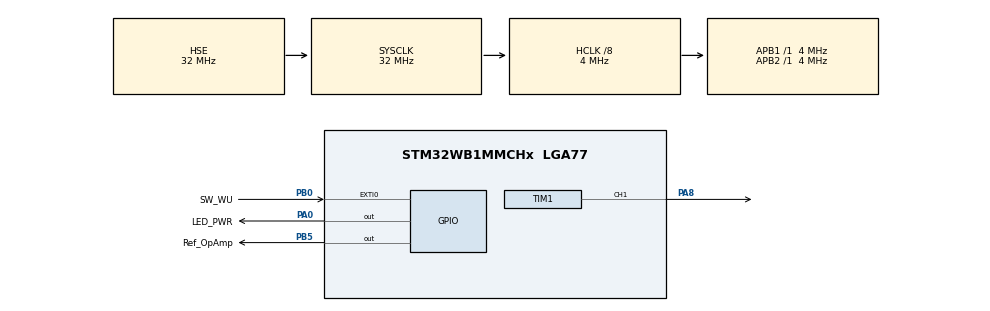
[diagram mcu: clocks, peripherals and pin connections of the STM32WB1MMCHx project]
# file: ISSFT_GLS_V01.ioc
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Mcu.Family=STM32WB
Mcu.Name=STM32WB1MMCHx
Mcu.Package=LGA77
NVIC.EXTI0_IRQn=true\:0\:0\:false\:false\:true\:true\:true\:true
NVIC.HSEM_IRQn=true\:0\:0\:false\:false\:true\:false\:true\:true
NVIC.IPCC_C1_RX_IRQn=true\:0\:0\:false\:false\:true\:true\:true\:true
NVIC.IPCC_C1_TX_IRQn=true\:0\:0\:false\:false\:true\:true\:true\:true
NVIC.PriorityGroup=NVIC_PRIORITYGROUP_4
NVIC.RCC_IRQn=true\:0\:0\:false\:false\:true\:true\:false\:true
NVIC.RTC_WKUP_IRQn=true\:0\:0\:false\:false\:true\:true\:true\:true
PA0.GPIO_Label=LED_PWR
PA0.GPIO_PuPd=GPIO_PULLDOWN
PA0.Signal=GPIO_Output
PA8.Signal=S_TIM1_CH1
PB0.GPIO_Label=SW_WU
PB0.GPIO_PuPd=GPIO_PULLUP
PB0.Signal=GPXTI0
PB5.GPIO_Label=Ref_OpAmp
PB5.GPIO_PuPd=GPIO_PULLDOWN
PB5.Signal=GPIO_Output
ProjectManager.HeapSize=0x400
ProjectManager.StackSize=0x1000
ProjectManager.TargetToolchain=STM32CubeIDE
RCC.AHB3CLKDivider=RCC_SYSCLK_DIV2
RCC.AHBCLKDivider=RCC_SYSCLK_DIV8
RCC.AHBFreq_Value=4000000
RCC.APB1Freq_Value=4000000
RCC.APB1TimFreq_Value=4000000
RCC.APB2Freq_Value=4000000
RCC.APB2TimFreq_Value=4000000
RCC.APB3Freq_Value=16000000
RCC.Cortex2_Div=SYSTICK_CLKSOURCE_HCLK_DIV8
RCC.CortexFreq_Value=4000000
RCC.HCLKFreq_Value=4000000
RCC.HSE_VALUE=32000000
RCC.HSI_VALUE=16000000
RCC.RFWKPClockSelection=RCC_RFWKPCLKSOURCE_LSE
RCC.RTCClockSelection=RCC_RTCCLKSOURCE_LSE
RCC.SMPSCLockSelectionVirtual=RCC_SMPSCLKSOURCE_HSE
RCC.SMPSDivider=4
RCC.SYSCLKFreq_VALUE=32000000
RCC.SYSCLKSource=RCC_SYSCLKSOURCE_HSE
RCC.VCOOutputFreq_Value=32000000
SH.S_TIM1_CH1.0=TIM1_CH1,PWM Generation1 CH1
STM32_WPAN.BLE_DBG_P2P_STM_EN=1
STM32_WPAN.CFG_BONDING_MODE=1
STM32_WPAN.CFG_DEBUGGER_SUPPORTED=0
STM32_WPAN.CFG_LPM_STANDBY_SUPPORTED=1
STM32_WPAN.CFG_LPM_SUPPORTED=1
STM32_WPAN.LOCAL_NAME=ISSFT_G
STM32_WPAN.LOCAL_NAME_FORMATTED=,'I','S','S','F','T','_','G'
STM32_WPAN.P2P_SERVER_NUMBER=P2P_SERVER1
TIM1.Channel-PWM\ Generation1\ CH1=TIM_CHANNEL_1
TIM1.Period=159
TIM1.Prescaler=3332
TIM1.Pulse-PWM\ Generation1\ CH1=79
VP_HSEM_VS_HSEM.Mode=HSEM_Activate
VP_IPCC_VS_IPCC.Mode=IPCC_Activate
VP_MEMORYMAP_VS_MEMORYMAP.Mode=CurAppReg
VP_RCC_V_OSC32_IN.Mode=LSE-External-Clock-Source
VP_RCC_V_OSC_IN.Mode=HSE-External-Clock-Source
VP_RF_VS_RF.Mode=RF_Activate
VP_RTC_VS_RTC_Activate.Mode=RTC_Enabled
VP_RTC_VS_RTC_WakeUp_intern.Mode=WakeUp
VP_SEQUENCER_VS_SEQUENCER.Mode=SEQUENCER_Enabled
VP_STM32_WPAN_VS_BLE_HOST.Mode=STM32_WPAN_Enabled
VP_TINY_LPM_VS_TINY_LPM.Mode=TINY_LPM_Enabled
board=custom

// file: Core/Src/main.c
/* USER CODE BEGIN Header */
/**
  ******************************************************************************
  * @file           : main.c
  * @brief          : Main program body
  ******************************************************************************
  * @attention
  *
  * Copyright (c) 2024 STMicroelectronics.
  * All rights reserved.
  *
  * This software is licensed under terms that can be found in the LICENSE file
  * in the root directory of this software component.
  * If no LICENSE file comes with this software, it is provided AS-IS.
  *
  ******************************************************************************
  */
/* USER CODE END Header */
#include "main.h"

IPCC_HandleTypeDef hipcc;

RTC_HandleTypeDef hrtc;

TIM_HandleTypeDef htim1;

void SystemClock_Config(void);
void PeriphCommonClock_Config(void);
static void MX_GPIO_Init(void);
static void MX_IPCC_Init(void);
static void MX_RTC_Init(void);
static void MX_TIM1_Init(void);
static void MX_RF_Init(void);
/* USER CODE BEGIN PFP */
static void MX_NVIC_DISABLE(void);
/* USER CODE END PFP */

int main(void)
{

  /* MCU Configuration--------------------------------------------------------*/

  /* Reset of all peripherals, Initializes the Flash interface and the Systick. */
  HAL_Init();
  /* Config code for STM32_WPAN (HSE Tuning must be done before system clock configuration) */
  MX_APPE_Config();

  /* Configure the system clock */
  SystemClock_Config();

/* Configure the peripherals common clocks */
  PeriphCommonClock_Config();

  /* IPCC initialisation */
  MX_IPCC_Init();

  /* Initialize all configured peripherals */
  MX_GPIO_Init();
  MX_RTC_Init();
  MX_TIM1_Init();
  MX_RF_Init();
  /* USER CODE BEGIN 2 */
//  MX_NVIC_DISABLE();
  /* USER CODE END 2 */

  /* Init code for STM32_WPAN */
  MX_APPE_Init();

  /* Infinite loop */
  while (1)
  {
    MX_APPE_Process();

    /* USER CODE BEGIN 3 */
    Task500ms();
    Task1000ms();
  }
  /* USER CODE END 3 */
}

void SystemClock_Config(void)
{
  RCC_OscInitTypeDef RCC_OscInitStruct = {0};
  RCC_ClkInitTypeDef RCC_ClkInitStruct = {0};

  /** Configure LSE Drive Capability
  */
  HAL_PWR_EnableBkUpAccess();
  __HAL_RCC_LSEDRIVE_CONFIG(RCC_LSEDRIVE_MEDIUMHIGH);

  /** Initializes the RCC Oscillators according to the specified parameters
  * in the RCC_OscInitTypeDef structure.
  */
  RCC_OscInitStruct.OscillatorType = RCC_OSCILLATORTYPE_HSI|RCC_OSCILLATORTYPE_HSE
                              |RCC_OSCILLATORTYPE_LSE;
  RCC_OscInitStruct.HSEState = RCC_HSE_ON;
  RCC_OscInitStruct.LSEState = RCC_LSE_ON;
  RCC_OscInitStruct.HSIState = RCC_HSI_ON;
  RCC_OscInitStruct.HSICalibrationValue = RCC_HSICALIBRATION_DEFAULT;
  RCC_OscInitStruct.PLL.PLLState = RCC_PLL_NONE;
  if (HAL_RCC_OscConfig(&RCC_OscInitStruct) != HAL_OK)
  {
    Error_Handler();
  }

  /** Configure the SYSCLKSource, HCLK, PCLK1 and PCLK2 clocks dividers
  */
  RCC_ClkInitStruct.ClockType = RCC_CLOCKTYPE_HCLK4|RCC_CLOCKTYPE_HCLK2
                              |RCC_CLOCKTYPE_HCLK|RCC_CLOCKTYPE_SYSCLK
                              |RCC_CLOCKTYPE_PCLK1|RCC_CLOCKTYPE_PCLK2;
  RCC_ClkInitStruct.SYSCLKSource = RCC_SYSCLKSOURCE_HSE;
  RCC_ClkInitStruct.AHBCLKDivider = RCC_SYSCLK_DIV8;
  RCC_ClkInitStruct.APB1CLKDivider = RCC_HCLK_DIV1;
  RCC_ClkInitStruct.APB2CLKDivider = RCC_HCLK_DIV1;
  RCC_ClkInitStruct.AHBCLK2Divider = RCC_SYSCLK_DIV1;
  RCC_ClkInitStruct.AHBCLK4Divider = RCC_SYSCLK_DIV2;

  if (HAL_RCC_ClockConfig(&RCC_ClkInitStruct, FLASH_LATENCY_0) != HAL_OK)
  {
    Error_Handler();
  }
}

void PeriphCommonClock_Config(void)
{
  RCC_PeriphCLKInitTypeDef PeriphClkInitStruct = {0};

  /** Initializes the peripherals clock
  */
  PeriphClkInitStruct.PeriphClockSelection = RCC_PERIPHCLK_SMPS|RCC_PERIPHCLK_RFWAKEUP;
  PeriphClkInitStruct.RFWakeUpClockSelection = RCC_RFWKPCLKSOURCE_LSE;
  PeriphClkInitStruct.SmpsClockSelection = RCC_SMPSCLKSOURCE_HSE;
  PeriphClkInitStruct.SmpsDivSelection = RCC_SMPSCLKDIV_RANGE1;

  if (HAL_RCCEx_PeriphCLKConfig(&PeriphClkInitStruct) != HAL_OK)
  {
    Error_Handler();
  }
}

static void MX_IPCC_Init(void)
{

  hipcc.Instance = IPCC;
  if (HAL_IPCC_Init(&hipcc) != HAL_OK)
  {
    Error_Handler();
  }

}

static void MX_RF_Init(void)
{

}

static void MX_RTC_Init(void)
{

  /** Initialize RTC Only
  */
  hrtc.Instance = RTC;
  hrtc.Init.HourFormat = RTC_HOURFORMAT_24;
  hrtc.Init.AsynchPrediv = CFG_RTC_ASYNCH_PRESCALER;
  hrtc.Init.SynchPrediv = CFG_RTC_SYNCH_PRESCALER;
  hrtc.Init.OutPut = RTC_OUTPUT_DISABLE;
  hrtc.Init.OutPutPolarity = RTC_OUTPUT_POLARITY_HIGH;
  hrtc.Init.OutPutRemap = RTC_OUTPUT_REMAP_NONE;
  if (HAL_RTC_Init(&hrtc) != HAL_OK)
  {
    Error_Handler();
  }

  /** Enable the WakeUp
  */
  if (HAL_RTCEx_SetWakeUpTimer_IT(&hrtc, 0, RTC_WAKEUPCLOCK_RTCCLK_DIV16) != HAL_OK)
  {
    Error_Handler();
  }

}

static void MX_TIM1_Init(void)
{

  TIM_MasterConfigTypeDef sMasterConfig = {0};
  TIM_OC_InitTypeDef sConfigOC = {0};
  TIM_BreakDeadTimeConfigTypeDef sBreakDeadTimeConfig = {0};

  htim1.Instance = TIM1;
  htim1.Init.Prescaler = 3332;
  htim1.Init.CounterMode = TIM_COUNTERMODE_UP;
  htim1.Init.Period = 159;
  htim1.Init.ClockDivision = TIM_CLOCKDIVISION_DIV1;
  htim1.Init.RepetitionCounter = 0;
  htim1.Init.AutoReloadPreload = TIM_AUTORELOAD_PRELOAD_DISABLE;
  if (HAL_TIM_PWM_Init(&htim1) != HAL_OK)
  {
    Error_Handler();
  }
  sMasterConfig.MasterOutputTrigger = TIM_TRGO_RESET;
  sMasterConfig.MasterOutputTrigger2 = TIM_TRGO2_RESET;
  sMasterConfig.MasterSlaveMode = TIM_MASTERSLAVEMODE_DISABLE;
  if (HAL_TIMEx_MasterConfigSynchronization(&htim1, &sMasterConfig) != HAL_OK)
  {
    Error_Handler();
  }
  sConfigOC.OCMode = TIM_OCMODE_PWM1;
  sConfigOC.Pulse = 79;
  sConfigOC.OCPolarity = TIM_OCPOLARITY_HIGH;
  sConfigOC.OCNPolarity = TIM_OCNPOLARITY_HIGH;
  sConfigOC.OCFastMode = TIM_OCFAST_DISABLE;
  sConfigOC.OCIdleState = TIM_OCIDLESTATE_RESET;
  sConfigOC.OCNIdleState = TIM_OCNIDLESTATE_RESET;
  if (HAL_TIM_PWM_ConfigChannel(&htim1, &sConfigOC, TIM_CHANNEL_1) != HAL_OK)
  {
    Error_Handler();
  }
  sBreakDeadTimeConfig.OffStateRunMode = TIM_OSSR_DISABLE;
  sBreakDeadTimeConfig.OffStateIDLEMode = TIM_OSSI_DISABLE;
  sBreakDeadTimeConfig.LockLevel = TIM_LOCKLEVEL_OFF;
  sBreakDeadTimeConfig.DeadTime = 0;
  sBreakDeadTimeConfig.BreakState = TIM_BREAK_DISABLE;
  sBreakDeadTimeConfig.BreakPolarity = TIM_BREAKPOLARITY_HIGH;
  sBreakDeadTimeConfig.BreakFilter = 0;
  sBreakDeadTimeConfig.BreakAFMode = TIM_BREAK_AFMODE_INPUT;
  sBreakDeadTimeConfig.Break2State = TIM_BREAK2_DISABLE;
  sBreakDeadTimeConfig.Break2Polarity = TIM_BREAK2POLARITY_HIGH;
  sBreakDeadTimeConfig.Break2Filter = 0;
  sBreakDeadTimeConfig.Break2AFMode = TIM_BREAK_AFMODE_INPUT;
  sBreakDeadTimeConfig.AutomaticOutput = TIM_AUTOMATICOUTPUT_DISABLE;
  if (HAL_TIMEx_ConfigBreakDeadTime(&htim1, &sBreakDeadTimeConfig) != HAL_OK)
  {
    Error_Handler();
  }
  HAL_TIM_MspPostInit(&htim1);

}

static void MX_GPIO_Init(void)
{
  GPIO_InitTypeDef GPIO_InitStruct = {0};

  /* GPIO Ports Clock Enable */
  __HAL_RCC_GPIOA_CLK_ENABLE();
  __HAL_RCC_GPIOB_CLK_ENABLE();

  /*Configure GPIO pin Output Level */
  HAL_GPIO_WritePin(Ref_OpAmp_GPIO_Port, Ref_OpAmp_Pin, GPIO_PIN_RESET);

  /*Configure GPIO pin Output Level */
  HAL_GPIO_WritePin(LED_PWR_GPIO_Port, LED_PWR_Pin, GPIO_PIN_RESET);

  /*Configure GPIO pin : Ref_OpAmp_Pin */
  GPIO_InitStruct.Pin = Ref_OpAmp_Pin;
  GPIO_InitStruct.Mode = GPIO_MODE_OUTPUT_PP;
  GPIO_InitStruct.Pull = GPIO_PULLDOWN;
  GPIO_InitStruct.Speed = GPIO_SPEED_FREQ_LOW;
  HAL_GPIO_Init(Ref_OpAmp_GPIO_Port, &GPIO_InitStruct);

  /*Configure GPIO pin : LED_PWR_Pin */
  GPIO_InitStruct.Pin = LED_PWR_Pin;
  GPIO_InitStruct.Mode = GPIO_MODE_OUTPUT_PP;
  GPIO_InitStruct.Pull = GPIO_PULLDOWN;
  GPIO_InitStruct.Speed = GPIO_SPEED_FREQ_LOW;
  HAL_GPIO_Init(LED_PWR_GPIO_Port, &GPIO_InitStruct);

  /*Configure GPIO pin : SW_WU_Pin */
  GPIO_InitStruct.Pin = SW_WU_Pin;
  GPIO_InitStruct.Mode = GPIO_MODE_IT_RISING;
  GPIO_InitStruct.Pull = GPIO_PULLUP;
  HAL_GPIO_Init(SW_WU_GPIO_Port, &GPIO_InitStruct);

  /* EXTI interrupt init*/
  HAL_NVIC_SetPriority(EXTI0_IRQn, 0, 0);
  HAL_NVIC_EnableIRQ(EXTI0_IRQn);

}

/* USER CODE BEGIN 4 */
void MX_NVIC_DISABLE(void)
{
	HAL_NVIC_DisableIRQ(WWDG_IRQn);
	HAL_NVIC_DisableIRQ(USART1_IRQn);
	HAL_NVIC_DisableIRQ(TSC_IRQn);
}
/* USER CODE END 4 */

void Error_Handler(void)
{
  __disable_irq();
  while (1)
  {
  }
}
